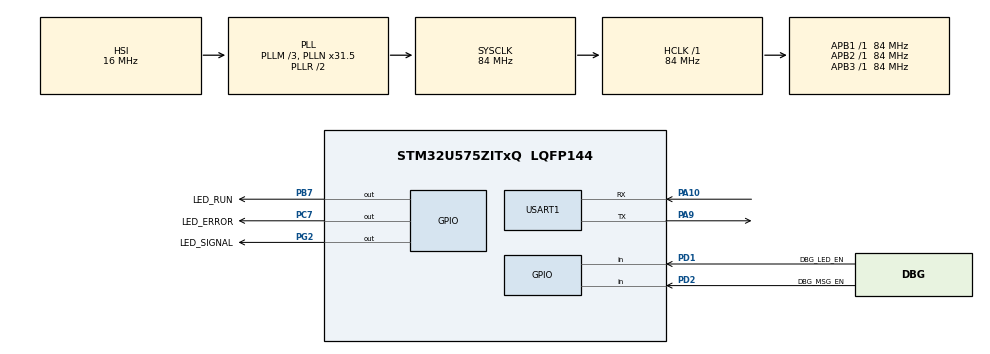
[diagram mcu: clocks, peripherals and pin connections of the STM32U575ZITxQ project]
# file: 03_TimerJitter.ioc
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CORTEX_M33_NS.userName=CORTEX_M33
Mcu.Family=STM32U5
Mcu.Name=STM32U575ZITxQ
Mcu.Package=LQFP144
NVIC.PriorityGroup=NVIC_PRIORITYGROUP_3
NVIC.TIM17_IRQn=true\:7\:0\:false\:false\:true\:false\:true\:true
NVIC.TimeBase=TIM17_IRQn
NVIC.TimeBaseIP=TIM17
PA10.Mode=Asynchronous
PA10.Signal=USART1_RX
PA13\ (JTMS/SWDIO).Signal=DEBUG_JTMS-SWDIO
PA14\ (JTCK/SWCLK).Signal=DEBUG_JTCK-SWCLK
PA9.Mode=Asynchronous
PA9.Signal=USART1_TX
PB3\ (JTDO/TRACESWO).Signal=DEBUG_JTDO-SWO
PB7.GPIO_Label=LED_RUN
PB7.Signal=GPIO_Output
PC14-OSC32_IN\ (PC14).Mode=LSE-External-Oscillator
PC14-OSC32_IN\ (PC14).Signal=RCC_OSC32_IN
PC15-OSC32_OUT\ (PC15).Mode=LSE-External-Oscillator
PC15-OSC32_OUT\ (PC15).Signal=RCC_OSC32_OUT
PC7.GPIO_Label=LED_ERROR
PC7.Signal=GPIO_Output
PD1.GPIO_Label=DBG_LED_EN
PD1.GPIO_PuPd=GPIO_PULLUP
PD1.Signal=GPIO_Input
PD2.GPIO_Label=DBG_MSG_EN
PD2.GPIO_PuPd=GPIO_PULLUP
PD2.Signal=GPIO_Input
PG2.GPIO_Label=LED_SIGNAL
PG2.Signal=GPIO_Output
PWR.PowerMode=PWR_SMPS_SUPPLY
ProjectManager.HeapSize=0x200
ProjectManager.StackSize=0x400
ProjectManager.TargetToolchain=STM32CubeIDE
RCC.ADCFreq_Value=16000000
RCC.AHBFreq_Value=84000000
RCC.APB1Freq_Value=84000000
RCC.APB1TimFreq_Value=84000000
RCC.APB2Freq_Value=84000000
RCC.APB2TimFreq_Value=84000000
RCC.APB3Freq_Value=84000000
RCC.CortexFreq_Value=84000000
RCC.DACCLockSelectionVirtual=RCC_DAC1CLKSOURCE_LSI
RCC.EPOD_VALUE=16000000
RCC.HCLKFreq_Value=84000000
RCC.HSE_VALUE=16000000
RCC.HSI48_VALUE=48000000
RCC.HSI_VALUE=16000000
RCC.LSIDIV_VALUE=32000
RCC.MSIClockRange=RCC_MSIRANGE_0
RCC.MSIKClockRange=RCC_MSIKRANGE_0
RCC.MSI_VALUE=48000000
RCC.PLL2FRACN=0
RCC.PLL3FRACN=0
RCC.PLLFRACN=4096
RCC.PLLM=3
RCC.PLLN=31
RCC.PLLSourceVirtual=RCC_PLLSOURCE_HSI
RCC.RTCClockSelection=RCC_RTCCLKSOURCE_LSE
RCC.SYSCLKFreq_VALUE=84000000
RCC.SYSCLKSource=RCC_SYSCLKSOURCE_PLLCLK
RCC.USBFreq_Value=48000000
RCC.VCOOutputFreq_Value=168000000
USART1.VirtualMode-Asynchronous=VM_ASYNC
VP_ICACHE_VS_ENABLE_ICACHE_MEMORY.Mode=Memoryregions
VP_ICACHE_VS_ICACHE.Mode=DirectMappedCache
VP_LPBAMQUEUE_VS_QUEUE.Mode=QUEUEMODE
VP_LPBAM_VS_SIG1.Mode=SmartRun
VP_LPBAM_VS_SIG4.Mode=LPDMA1
VP_MEMORYMAP_VS_MEMORYMAP.Mode=CurAppReg
VP_NUCLEO-U575ZI-Q_VS_BSP_COMMON.Mode=COMMON
VP_PWR_VS_DBSignals.Mode=DisableDeadBatterySignals
VP_PWR_VS_LPOM.Mode=PowerOptimisation
VP_PWR_VS_SECSignals.Mode=Security/Privilege
VP_SYS_VS_tim17.Mode=TIM17
board=NUCLEO-U575ZI-Q

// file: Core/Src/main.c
/* USER CODE BEGIN Header */
/**
  ******************************************************************************
  * @file           : main.c
  * @brief          : Main program body
  ******************************************************************************
  * @attention
  *
  * Copyright (c) 2026 STMicroelectronics.
  * All rights reserved.
  *
  * This software is licensed under terms that can be found in the LICENSE file
  * in the root directory of this software component.
  * If no LICENSE file comes with this software, it is provided AS-IS.
  *
  ******************************************************************************
  */
/* USER CODE END Header */
#include "main.h"

/* USER CODE BEGIN Includes */
#include "../../app/fm_main.h"
/* USER CODE END Includes */

UART_HandleTypeDef huart1;

void SystemClock_Config(void);
static void SystemPower_Config(void);
static void MX_GPIO_Init(void);
static void MX_ICACHE_Init(void);
static void MX_USART1_UART_Init(void);

int main(void)
{

  /* MCU Configuration--------------------------------------------------------*/

  /* Reset of all peripherals, Initializes the Flash interface and the Systick. */
  HAL_Init();

  /* Configure the System Power */
  SystemPower_Config();

  /* Configure the system clock */
  SystemClock_Config();

  /* Initialize all configured peripherals */
  MX_GPIO_Init();
  MX_ICACHE_Init();
  MX_USART1_UART_Init();

  /* Infinite loop */
  /* USER CODE BEGIN WHILE */
  while (1)
  {
      FM_MAIN_Main();

    /* USER CODE END WHILE */

  }
}

void SystemClock_Config(void)
{
  RCC_OscInitTypeDef RCC_OscInitStruct = {0};
  RCC_ClkInitTypeDef RCC_ClkInitStruct = {0};

  /** Configure the main internal regulator output voltage
  */
  if (HAL_PWREx_ControlVoltageScaling(PWR_REGULATOR_VOLTAGE_SCALE2) != HAL_OK)
  {
    Error_Handler();
  }

  /** Initializes the CPU, AHB and APB buses clocks
  */
  RCC_OscInitStruct.OscillatorType = RCC_OSCILLATORTYPE_HSI;
  RCC_OscInitStruct.HSIState = RCC_HSI_ON;
  RCC_OscInitStruct.HSICalibrationValue = RCC_HSICALIBRATION_DEFAULT;
  RCC_OscInitStruct.PLL.PLLState = RCC_PLL_ON;
  RCC_OscInitStruct.PLL.PLLSource = RCC_PLLSOURCE_HSI;
  RCC_OscInitStruct.PLL.PLLMBOOST = RCC_PLLMBOOST_DIV1;
  RCC_OscInitStruct.PLL.PLLM = 3;
  RCC_OscInitStruct.PLL.PLLN = 31;
  RCC_OscInitStruct.PLL.PLLP = 2;
  RCC_OscInitStruct.PLL.PLLQ = 2;
  RCC_OscInitStruct.PLL.PLLR = 2;
  RCC_OscInitStruct.PLL.PLLRGE = RCC_PLLVCIRANGE_0;
  RCC_OscInitStruct.PLL.PLLFRACN = 4096;
  if (HAL_RCC_OscConfig(&RCC_OscInitStruct) != HAL_OK)
  {
    Error_Handler();
  }

  /** Initializes the CPU, AHB and APB buses clocks
  */
  RCC_ClkInitStruct.ClockType = RCC_CLOCKTYPE_HCLK|RCC_CLOCKTYPE_SYSCLK
                              |RCC_CLOCKTYPE_PCLK1|RCC_CLOCKTYPE_PCLK2
                              |RCC_CLOCKTYPE_PCLK3;
  RCC_ClkInitStruct.SYSCLKSource = RCC_SYSCLKSOURCE_PLLCLK;
  RCC_ClkInitStruct.AHBCLKDivider = RCC_SYSCLK_DIV1;
  RCC_ClkInitStruct.APB1CLKDivider = RCC_HCLK_DIV1;
  RCC_ClkInitStruct.APB2CLKDivider = RCC_HCLK_DIV1;
  RCC_ClkInitStruct.APB3CLKDivider = RCC_HCLK_DIV1;

  if (HAL_RCC_ClockConfig(&RCC_ClkInitStruct, FLASH_LATENCY_2) != HAL_OK)
  {
    Error_Handler();
  }
}

/**
  * @brief Power Configuration
  * @retval None
  */
static void SystemPower_Config(void)
{
  HAL_PWREx_EnableVddIO2();

  /*
   * Disable the internal Pull-Up in Dead Battery pins of UCPD peripheral
   */
  HAL_PWREx_DisableUCPDDeadBattery();

  /*
   * Switch to SMPS regulator instead of LDO
   */
  if (HAL_PWREx_ConfigSupply(PWR_SMPS_SUPPLY) != HAL_OK)
  {
    Error_Handler();
  }
}

static void MX_ICACHE_Init(void)
{

  /** Enable instruction cache in 1-way (direct mapped cache)
  */
  if (HAL_ICACHE_ConfigAssociativityMode(ICACHE_1WAY) != HAL_OK)
  {
    Error_Handler();
  }
  if (HAL_ICACHE_Enable() != HAL_OK)
  {
    Error_Handler();
  }

}

static void MX_USART1_UART_Init(void)
{

  huart1.Instance = USART1;
  huart1.Init.BaudRate = 115200;
  huart1.Init.WordLength = UART_WORDLENGTH_8B;
  huart1.Init.StopBits = UART_STOPBITS_1;
  huart1.Init.Parity = UART_PARITY_NONE;
  huart1.Init.Mode = UART_MODE_TX_RX;
  huart1.Init.HwFlowCtl = UART_HWCONTROL_NONE;
  huart1.Init.OverSampling = UART_OVERSAMPLING_16;
  huart1.Init.OneBitSampling = UART_ONE_BIT_SAMPLE_DISABLE;
  huart1.Init.ClockPrescaler = UART_PRESCALER_DIV1;
  huart1.AdvancedInit.AdvFeatureInit = UART_ADVFEATURE_NO_INIT;
  if (HAL_UART_Init(&huart1) != HAL_OK)
  {
    Error_Handler();
  }
  if (HAL_UARTEx_SetTxFifoThreshold(&huart1, UART_TXFIFO_THRESHOLD_1_8) != HAL_OK)
  {
    Error_Handler();
  }
  if (HAL_UARTEx_SetRxFifoThreshold(&huart1, UART_RXFIFO_THRESHOLD_1_8) != HAL_OK)
  {
    Error_Handler();
  }
  if (HAL_UARTEx_DisableFifoMode(&huart1) != HAL_OK)
  {
    Error_Handler();
  }

}

static void MX_GPIO_Init(void)
{
  GPIO_InitTypeDef GPIO_InitStruct = {0};

  /* GPIO Ports Clock Enable */
  __HAL_RCC_GPIOC_CLK_ENABLE();
  __HAL_RCC_GPIOG_CLK_ENABLE();
  __HAL_RCC_GPIOA_CLK_ENABLE();
  __HAL_RCC_GPIOD_CLK_ENABLE();
  __HAL_RCC_GPIOB_CLK_ENABLE();

  /*Configure GPIO pin Output Level */
  HAL_GPIO_WritePin(LED_SIGNAL_GPIO_Port, LED_SIGNAL_Pin, GPIO_PIN_RESET);

  /*Configure GPIO pin Output Level */
  HAL_GPIO_WritePin(LED_ERROR_GPIO_Port, LED_ERROR_Pin, GPIO_PIN_RESET);

  /*Configure GPIO pin Output Level */
  HAL_GPIO_WritePin(LED_RUN_GPIO_Port, LED_RUN_Pin, GPIO_PIN_RESET);

  /*Configure GPIO pin : LED_SIGNAL_Pin */
  GPIO_InitStruct.Pin = LED_SIGNAL_Pin;
  GPIO_InitStruct.Mode = GPIO_MODE_OUTPUT_PP;
  GPIO_InitStruct.Pull = GPIO_NOPULL;
  GPIO_InitStruct.Speed = GPIO_SPEED_FREQ_LOW;
  HAL_GPIO_Init(LED_SIGNAL_GPIO_Port, &GPIO_InitStruct);

  /*Configure GPIO pin : LED_ERROR_Pin */
  GPIO_InitStruct.Pin = LED_ERROR_Pin;
  GPIO_InitStruct.Mode = GPIO_MODE_OUTPUT_PP;
  GPIO_InitStruct.Pull = GPIO_NOPULL;
  GPIO_InitStruct.Speed = GPIO_SPEED_FREQ_LOW;
  HAL_GPIO_Init(LED_ERROR_GPIO_Port, &GPIO_InitStruct);

  /*Configure GPIO pins : DBG_LED_EN_Pin DBG_MSG_EN_Pin */
  GPIO_InitStruct.Pin = DBG_LED_EN_Pin|DBG_MSG_EN_Pin;
  GPIO_InitStruct.Mode = GPIO_MODE_INPUT;
  GPIO_InitStruct.Pull = GPIO_PULLUP;
  HAL_GPIO_Init(GPIOD, &GPIO_InitStruct);

  /*Configure GPIO pin : LED_RUN_Pin */
  GPIO_InitStruct.Pin = LED_RUN_Pin;
  GPIO_InitStruct.Mode = GPIO_MODE_OUTPUT_PP;
  GPIO_InitStruct.Pull = GPIO_NOPULL;
  GPIO_InitStruct.Speed = GPIO_SPEED_FREQ_LOW;
  HAL_GPIO_Init(LED_RUN_GPIO_Port, &GPIO_InitStruct);

}

void HAL_TIM_PeriodElapsedCallback(TIM_HandleTypeDef *htim)
{
  if (htim->Instance == TIM17)
  {
    HAL_IncTick();
  }
}

void Error_Handler(void)
{
  __disable_irq();
  while (1)
  {
  }
}
